# NPCX490M register map
File version: 1.0
Registers are 8-bit, read-write, reset 0x0 unless marked. A register's access mark holds for its fields unless they carry their own. Offsets are from the block's base; [hi:lo] are bit positions; lines under a group give offsets from that group; {n}, {i} and the like mark numbered series.

## GDMA1
Base 0x40011000
Same registers: GDMA2 0x40011A00
{0x0+0x20*i} CHANNEL{i} (i=0..1) group
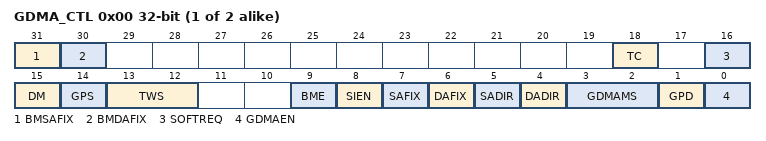
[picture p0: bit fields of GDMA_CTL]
  0x00 GDMA_CTL 32-bit (reset mask 0xFF) — Channel 0/1 Control Register
    [31] BMSAFIX — Burst Mode Source Address Fixed
    [30] BMDAFIX — Burst Mode Destination Address Fixed
    [18] TC write-0-clears — Terminal Count
    [16] SOFTREQ wo — Software Triggered GDMA Request
    [15] DM — Demand Mode
    [14] GPS — GDMA Power Save
    [13:12] TWS — Transfer Width Select
    [9] BME — Burst Mode Enable
    [8] SIEN — Stop Interrupt Enable
    [7] SAFIX — Source Address Fixed
    [6] DAFIX — Destination Address Fixed
    [5] SADIR — Source Address Direction
    [4] DADIR — Destination Address Direction
    [3:2] GDMAMS — GDMA Mode Select
    [1] GPD — GDMA Power-Down
    [0] GDMAEN — GDMA Enable
  0x04 GDMA_SRCB 32-bit (reset mask 0xFF) — Channel 0/1 Source Base Address Register
  0x08 GDMA_DSTB 32-bit (reset mask 0xFF) — Channel 0/1 Destination Base Address Register
  0x0C GDMA_TCNT 32-bit (reset mask 0xFF) — Channel 0/1 Transfer Count Register
    [23:0] TFR_CNT — 24-bit Transfer Count
  0x10 GDMA_CSRC 32-bit ro (reset mask 0xFF) — Channel 0/1 Current Source Register
    [31:0] CURRENT_SRC_ADDR — 32-bit Current Source Address
  0x14 GDMA_CDST 32-bit ro (reset mask 0xFF) — Channel 0/1 Current Destination Register
    [31:0] CURRENT_DST_ADDR — 32-bit Current Destination Address
  0x18 GDMA_CTCNT 32-bit ro (reset mask 0xFF) — Channel 0/1 Current Transfer Count Register
    [23:0] CURENT_TFR_CNT — Current Transfer Count
  0x1C GDMA_REQ_SL 32-bit — Channel 0/1 GDMA Request Select Register
    [15:0] DREQ_SL — DMA Request Select

## GPIO0
Base 0x40081000
Same registers: GPIO{n} {0x40081000+0x2000*n} (n=1..9), GPIOA 0x40095000, GPIOB 0x40097000, GPIOC 0x40099000, GPIOD 0x4009B000, GPIOE 0x4009D000, GPIOF 0x4009F000
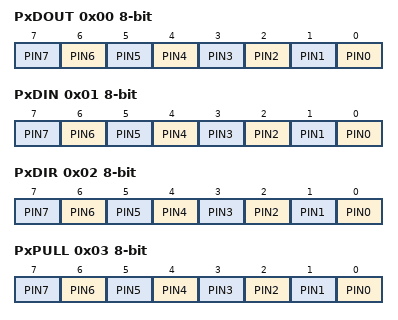
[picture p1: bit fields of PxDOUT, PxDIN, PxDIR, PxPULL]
0x00 PxDOUT — Port GPIOx Data Out Register (PxDOUT)
  [n] PIN{n} (n=0..7) — Data Out for Pin {n}
    0=Low; 1=High
0x01 PxDIN — Port GPIOx Data In Register (PxDIN)
  [n] PIN{n} (n=0..7) — Data In for Pin {n}
    0=Low; 1=High
0x02 PxDIR — Port GPIOx Direction Register (PxDIR)
  [n] PIN{n} (n=0..7) — Direction control for Pin {n}
    0=Input; 1=Output
0x03 PxPULL — Port GPIOx Pull-Up or Pull-Down Enable Register (PxPULL)
  [n] PIN{n} (n=0..7) — Pull-up or pull-down control for Pin {n}
    0=Disable; 1=Enable
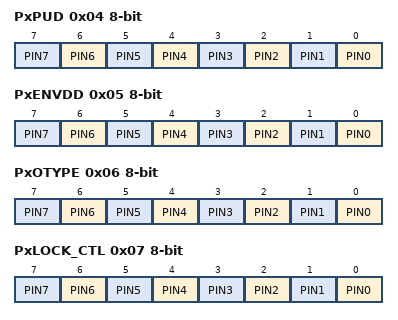
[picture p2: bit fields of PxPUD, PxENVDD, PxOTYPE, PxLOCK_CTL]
0x04 PxPUD — Port GPIOx Pull-Up/Down Selection Register (PxPUD)
  [n] PIN{n} (n=0..7) — Pull-up or pull-down selection for Pin {n}
    0=PullUp; 1=PullDown
0x05 PxENVDD — Port GPIOx Drive Enable by VDD Present Register (PxENVDD)
  [n] PIN{n} (n=0..7) — Drive Enable by Vdd Present for Pin {n}
    0=Enable; 1=Disable
0x06 PxOTYPE — Port GPIOx Output Type Register (PxOTYPE)
  [n] PIN{n} (n=0..7) — Output Type selection for Pin {n}
    0=PushPull; 1=OpenDrain
0x07 PxLOCK_CTL — Port GPIOx Lock Control Register (PxLOCK_CTL)
  [n] PIN{n} (n=0..7) — Output Data and Configuration Lock for Pin {n}
    0=Unlock; 1=Lock

## HFCG
Base 0x400B5000
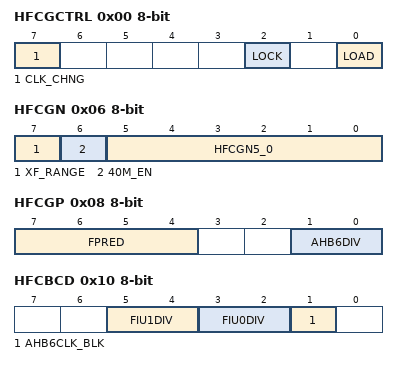
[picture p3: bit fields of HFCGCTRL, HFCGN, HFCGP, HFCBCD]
0x00 HFCGCTRL — HFCG Control Register (HFCGCTRL)
  [7] CLK_CHNG — Clock Changing
  [2] LOCK — Disable Writing to all HFCG registers
  [0] LOAD — Load M and N Values
0x02 HFCGML — HFCG M Low Value Register (HFCGML)
0x04 HFCGMH — HFCG M High Value Register (HFCGMH)
0x06 HFCGN — HFCG N Value Register (HFCGN)
  [7] XF_RANGE — Extended Frequency Range
  [6] 40M_EN — 40 MHz Enable
  [5:0] HFCGN5_0 — N Value Bits 5-0
0x08 HFCGP — HFCG Prescaler Register (HFCGP)
  [7:4] FPRED — Core Clock Prescaler Divider Value
  [1:0] AHB6DIV — AHB6 Clock Divider
0x10 HFCBCD — HFCG Bus Clock Dividers Register (HFCBCD)
  [5:4] FIU1DIV — FIU1 Clock Divider
  [3:2] FIU0DIV — FIU0 Clock Divider
  [1] AHB6CLK_BLK — AHB6 Clock Block
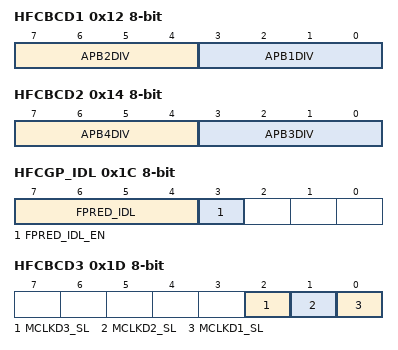
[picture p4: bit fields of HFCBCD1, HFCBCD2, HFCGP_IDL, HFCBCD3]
0x12 HFCBCD1 — HFCG Bus Clock Dividers 1 Register (HFCBCD1)
  [7:4] APB2DIV — APB2 Clock Divider
  [3:0] APB1DIV — APB1 Clock Divider
0x14 HFCBCD2 — HFCG Bus Clock Dividers 2 Register (HFCBCD2)
  [7:4] APB4DIV — APB4 Clock Divider
  [3:0] APB3DIV — APB3 Clock Divider
0x1C HFCGP_IDL — HFCG Prescaler in Idle Register (HFCGP_IDL)
  [7:4] FPRED_IDL — Core Clock Prescaler Divider in Idle Value
  [3] FPRED_IDL_EN — Core Clock Prescaler Divider in Idle Value Enable
0x1D HFCBCD3 — HFCG Bus Clock Dividers 3 Register (HFCBCD3)
  [2] MCLKD3_SL — MCLK Division for I3CI3 Select
  [1] MCLKD2_SL — MCLK Division for I3CI2 Select
  [0] MCLKD1_SL — MCLK Division for I3CI1 Select
